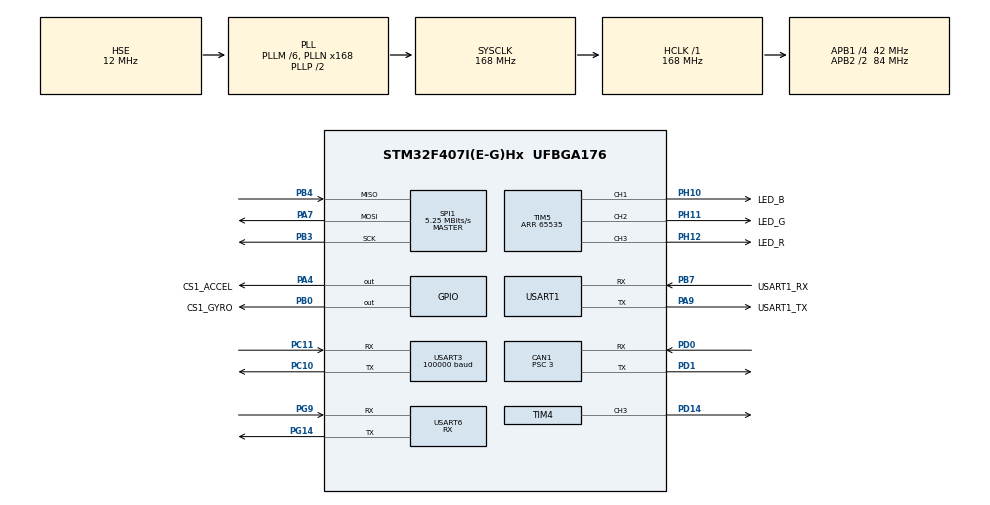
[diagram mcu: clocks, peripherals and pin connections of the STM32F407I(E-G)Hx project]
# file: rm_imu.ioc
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CAN1.ABOM=ENABLE
CAN1.BS1=CAN_BS1_11TQ
CAN1.BS2=CAN_BS2_2TQ
CAN1.CalculateBaudRate=1000000
CAN1.CalculateTimeBit=1000
CAN1.CalculateTimeQuantum=71.42857142857143
CAN1.NART=ENABLE
CAN1.Prescaler=3
Dma.Request0=USART3_RX
Dma.Request1=USART6_RX
Dma.USART3_RX.0.Direction=DMA_PERIPH_TO_MEMORY
Dma.USART3_RX.0.FIFOMode=DMA_FIFOMODE_DISABLE
Dma.USART3_RX.0.Instance=DMA1_Stream1
Dma.USART3_RX.0.MemDataAlignment=DMA_MDATAALIGN_BYTE
Dma.USART3_RX.0.MemInc=DMA_MINC_ENABLE
Dma.USART3_RX.0.Mode=DMA_NORMAL
Dma.USART3_RX.0.PeriphDataAlignment=DMA_PDATAALIGN_BYTE
Dma.USART3_RX.0.PeriphInc=DMA_PINC_DISABLE
Dma.USART3_RX.0.Priority=DMA_PRIORITY_HIGH
Dma.USART6_RX.1.Direction=DMA_PERIPH_TO_MEMORY
Dma.USART6_RX.1.FIFOMode=DMA_FIFOMODE_DISABLE
Dma.USART6_RX.1.Instance=DMA2_Stream1
Dma.USART6_RX.1.MemDataAlignment=DMA_MDATAALIGN_BYTE
Dma.USART6_RX.1.MemInc=DMA_MINC_ENABLE
Dma.USART6_RX.1.Mode=DMA_NORMAL
Dma.USART6_RX.1.PeriphDataAlignment=DMA_PDATAALIGN_BYTE
Dma.USART6_RX.1.PeriphInc=DMA_PINC_DISABLE
Dma.USART6_RX.1.Priority=DMA_PRIORITY_MEDIUM
FREERTOS.Tasks01=defaultTask,0,128,StartDefaultTask,Default,NULL,Dynamic,NULL,NULL;imutask,2,512,imu_task,As external,NULL,Dynamic,NULL,NULL;plotTask,-2,512,plot_task,As external,NULL,Dynamic,NULL,NULL;remoteTask,0,512,remote_task,As external,NULL,Dynamic,NULL,NULL;ledtask,-2,512,led_task,As external,NULL,Dynamic,NULL,NULL;buzzerTask,-3,512,buzzer_task,As external,NULL,Dynamic,NULL,NULL;controlTask,3,512,control_task,As external,NULL,Dynamic,NULL,NULL
Mcu.Family=STM32F4
Mcu.Name=STM32F407I(E-G)Hx
Mcu.Package=UFBGA176
NVIC.CAN1_RX0_IRQn=true\:5\:0\:false\:false\:true\:true\:true\:true\:true
NVIC.DMA1_Stream1_IRQn=true\:5\:0\:false\:false\:true\:true\:false\:true\:true
NVIC.DMA2_Stream1_IRQn=true\:5\:0\:false\:false\:true\:true\:false\:true\:true
NVIC.PriorityGroup=NVIC_PRIORITYGROUP_4
NVIC.TIM6_DAC_IRQn=true\:15\:0\:false\:false\:true\:false\:false\:true\:true
NVIC.TimeBase=TIM6_DAC_IRQn
NVIC.TimeBaseIP=TIM6
NVIC.USART3_IRQn=true\:5\:0\:false\:false\:true\:true\:true\:true\:true
NVIC.USART6_IRQn=true\:5\:0\:false\:false\:true\:true\:true\:true\:true
PA13.Mode=Serial_Wire
PA13.Signal=SYS_JTMS-SWDIO
PA14.Mode=Serial_Wire
PA14.Signal=SYS_JTCK-SWCLK
PA4.GPIO_Label=CS1_ACCEL
PA4.GPIO_Speed=GPIO_SPEED_FREQ_VERY_HIGH
PA4.PinState=GPIO_PIN_SET
PA4.Signal=GPIO_Output
PA7.Mode=Full_Duplex_Master
PA7.Signal=SPI1_MOSI
PA9.GPIO_Label=USART1_TX
PA9.Mode=Asynchronous
PA9.Signal=USART1_TX
PB0.GPIO_Label=CS1_GYRO
PB0.GPIO_Speed=GPIO_SPEED_FREQ_VERY_HIGH
PB0.PinState=GPIO_PIN_SET
PB0.Signal=GPIO_Output
PB3.Mode=Full_Duplex_Master
PB3.Signal=SPI1_SCK
PB4.Mode=Full_Duplex_Master
PB4.Signal=SPI1_MISO
PB7.GPIO_Label=USART1_RX
PB7.Mode=Asynchronous
PB7.Signal=USART1_RX
PC10.Mode=Asynchronous
PC10.Signal=USART3_TX
PC11.Mode=Asynchronous
PC11.Signal=USART3_RX
PD0.Mode=CAN_Activate
PD0.Signal=CAN1_RX
PD1.Mode=CAN_Activate
PD1.Signal=CAN1_TX
PD14.Signal=S_TIM4_CH3
PG14.Mode=Asynchronous
PG14.Signal=USART6_TX
PG9.Mode=Asynchronous
PG9.Signal=USART6_RX
PH0-OSC_IN.Mode=HSE-External-Oscillator
PH0-OSC_IN.Signal=RCC_OSC_IN
PH1-OSC_OUT.Mode=HSE-External-Oscillator
PH1-OSC_OUT.Signal=RCC_OSC_OUT
PH10.GPIO_Label=LED_B
PH10.Signal=S_TIM5_CH1
PH11.GPIO_Label=LED_G
PH11.Signal=S_TIM5_CH2
PH12.GPIO_Label=LED_R
PH12.Signal=S_TIM5_CH3
ProjectManager.HeapSize=0x200
ProjectManager.StackSize=0x400
ProjectManager.TargetToolchain=CMake
RCC.48MHZClocksFreq_Value=84000000
RCC.AHBFreq_Value=168000000
RCC.APB1CLKDivider=RCC_HCLK_DIV4
RCC.APB1Freq_Value=42000000
RCC.APB1TimFreq_Value=84000000
RCC.APB2CLKDivider=RCC_HCLK_DIV2
RCC.APB2Freq_Value=84000000
RCC.APB2TimFreq_Value=168000000
RCC.CortexFreq_Value=168000000
RCC.HCLKFreq_Value=168000000
RCC.HSE_VALUE=12000000
RCC.HSI_VALUE=16000000
RCC.LSE_VALUE=32768
RCC.PLLM=6
RCC.PLLN=168
RCC.PLLSourceVirtual=RCC_PLLSOURCE_HSE
RCC.SYSCLKFreq_VALUE=168000000
RCC.SYSCLKSource=RCC_SYSCLKSOURCE_PLLCLK
RCC.VCOOutputFreq_Value=336000000
SH.S_TIM4_CH3.0=TIM4_CH3,PWM Generation3 CH3
SH.S_TIM5_CH1.0=TIM5_CH1,PWM Generation1 CH1
SH.S_TIM5_CH2.0=TIM5_CH2,PWM Generation2 CH2
SH.S_TIM5_CH3.0=TIM5_CH3,PWM Generation3 CH3
SPI1.BaudRatePrescaler=SPI_BAUDRATEPRESCALER_16
SPI1.CLKPhase=SPI_PHASE_2EDGE
SPI1.CLKPolarity=SPI_POLARITY_HIGH
SPI1.CalculateBaudRate=5.25 MBits/s
SPI1.Direction=SPI_DIRECTION_2LINES
SPI1.Mode=SPI_MODE_MASTER
SPI1.VirtualType=VM_MASTER
TIM4.Channel-PWM\ Generation3\ CH3=TIM_CHANNEL_3
TIM4.Period=249
TIM4.Prescaler=83
TIM4.Pulse-PWM\ Generation3\ CH3=125
TIM5.Channel-PWM\ Generation1\ CH1=TIM_CHANNEL_1
TIM5.Channel-PWM\ Generation2\ CH2=TIM_CHANNEL_2
TIM5.Channel-PWM\ Generation3\ CH3=TIM_CHANNEL_3
TIM5.Period=65535
USART1.VirtualMode=VM_ASYNC
USART3.BaudRate=100000
USART3.Mode=MODE_RX
USART3.Parity=PARITY_EVEN
USART3.VirtualMode=VM_ASYNC
USART3.WordLength=WORDLENGTH_9B
USART6.Mode=MODE_RX
USART6.VirtualMode=VM_ASYNC
VP_FREERTOS_VS_CMSIS_V1.Mode=CMSIS_V1
VP_SYS_VS_tim6.Mode=TIM6
VP_TIM4_VS_ClockSourceINT.Mode=Internal
VP_TIM5_VS_ClockSourceINT.Mode=Internal
board=custom

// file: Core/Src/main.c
/* USER CODE BEGIN Header */
/**
  ******************************************************************************
  * @file           : main.c
  * @brief          : Main program body
  ******************************************************************************
  * @attention
  *
  * Copyright (c) 2026 STMicroelectronics.
  * All rights reserved.
  *
  * This software is licensed under terms that can be found in the LICENSE file
  * in the root directory of this software component.
  * If no LICENSE file comes with this software, it is provided AS-IS.
  *
  ******************************************************************************
  */
/* USER CODE END Header */
#include "main.h"
#include "cmsis_os.h"
#include "can.h"
#include "dma.h"
#include "spi.h"
#include "tim.h"
#include "usart.h"
#include "gpio.h"

void SystemClock_Config(void);
void MX_FREERTOS_Init(void);

int main(void)
{

  /* MCU Configuration--------------------------------------------------------*/

  /* Reset of all peripherals, Initializes the Flash interface and the Systick. */
  HAL_Init();

  /* Configure the system clock */
  SystemClock_Config();

  /* Initialize all configured peripherals */
  MX_GPIO_Init();
  MX_DMA_Init();
  MX_SPI1_Init();
  MX_USART1_UART_Init();
  MX_USART3_UART_Init();
  MX_CAN1_Init();
  MX_TIM5_Init();
  MX_TIM4_Init();
  MX_USART6_UART_Init();

  /* Call init function for freertos objects (in cmsis_os2.c) */
  MX_FREERTOS_Init();

  /* Start scheduler */
  osKernelStart();

  /* We should never get here as control is now taken by the scheduler */

  /* Infinite loop */
  while (1)
  {

  }
}

void SystemClock_Config(void)
{
  RCC_OscInitTypeDef RCC_OscInitStruct = {0};
  RCC_ClkInitTypeDef RCC_ClkInitStruct = {0};

  /** Configure the main internal regulator output voltage
  */
  __HAL_RCC_PWR_CLK_ENABLE();
  __HAL_PWR_VOLTAGESCALING_CONFIG(PWR_REGULATOR_VOLTAGE_SCALE1);

  /** Initializes the RCC Oscillators according to the specified parameters
  * in the RCC_OscInitTypeDef structure.
  */
  RCC_OscInitStruct.OscillatorType = RCC_OSCILLATORTYPE_HSE;
  RCC_OscInitStruct.HSEState = RCC_HSE_ON;
  RCC_OscInitStruct.PLL.PLLState = RCC_PLL_ON;
  RCC_OscInitStruct.PLL.PLLSource = RCC_PLLSOURCE_HSE;
  RCC_OscInitStruct.PLL.PLLM = 6;
  RCC_OscInitStruct.PLL.PLLN = 168;
  RCC_OscInitStruct.PLL.PLLP = RCC_PLLP_DIV2;
  RCC_OscInitStruct.PLL.PLLQ = 4;
  if (HAL_RCC_OscConfig(&RCC_OscInitStruct) != HAL_OK)
  {
    Error_Handler();
  }

  /** Initializes the CPU, AHB and APB buses clocks
  */
  RCC_ClkInitStruct.ClockType = RCC_CLOCKTYPE_HCLK|RCC_CLOCKTYPE_SYSCLK
                              |RCC_CLOCKTYPE_PCLK1|RCC_CLOCKTYPE_PCLK2;
  RCC_ClkInitStruct.SYSCLKSource = RCC_SYSCLKSOURCE_PLLCLK;
  RCC_ClkInitStruct.AHBCLKDivider = RCC_SYSCLK_DIV1;
  RCC_ClkInitStruct.APB1CLKDivider = RCC_HCLK_DIV4;
  RCC_ClkInitStruct.APB2CLKDivider = RCC_HCLK_DIV2;

  if (HAL_RCC_ClockConfig(&RCC_ClkInitStruct, FLASH_LATENCY_5) != HAL_OK)
  {
    Error_Handler();
  }
}

void HAL_TIM_PeriodElapsedCallback(TIM_HandleTypeDef *htim)
{
  if (htim->Instance == TIM6)
  {
    HAL_IncTick();
  }
}

void Error_Handler(void)
{
  __disable_irq();
  while (1)
  {
  }
}

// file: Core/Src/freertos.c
/* USER CODE BEGIN Header */
/**
  ******************************************************************************
  * File Name          : freertos.c
  * Description        : Code for freertos applications
  ******************************************************************************
  * @attention
  *
  * Copyright (c) 2026 STMicroelectronics.
  * All rights reserved.
  *
  * This software is licensed under terms that can be found in the LICENSE file
  * in the root directory of this software component.
  * If no LICENSE file comes with this software, it is provided AS-IS.
  *
  ******************************************************************************
  */
/* USER CODE END Header */

#include "FreeRTOS.h"
#include "task.h"
#include "main.h"
#include "cmsis_os.h"

/* USER CODE BEGIN Includes */
#include "imu_task.h"
#include "remote_task.h"
#include "can_task.h"
/* USER CODE END Includes */

osThreadId defaultTaskHandle;
osThreadId imutaskHandle;
osThreadId usartTaskHandle;
osThreadId remoteTaskHandle;
osThreadId ledtaskHandle;
osThreadId buzzerTaskHandle;
osThreadId controlTaskHandle;

void StartDefaultTask(void const * argument);
extern void imu_task(void const * argument);
extern void usart_task(void const * argument);
extern void remote_task(void const * argument);
extern void led_task(void const * argument);
extern void buzzer_task(void const * argument);
extern void control_task(void const * argument);

void MX_FREERTOS_Init(void); /* (MISRA C 2004 rule 8.1) */

/* GetIdleTaskMemory prototype (linked to static allocation support) */
void vApplicationGetIdleTaskMemory( StaticTask_t **ppxIdleTaskTCBBuffer, StackType_t **ppxIdleTaskStackBuffer, uint32_t *pulIdleTaskStackSize );

/* USER CODE BEGIN GET_IDLE_TASK_MEMORY */
static StaticTask_t xIdleTaskTCBBuffer;
static StackType_t xIdleStack[configMINIMAL_STACK_SIZE];

void vApplicationGetIdleTaskMemory( StaticTask_t **ppxIdleTaskTCBBuffer, StackType_t **ppxIdleTaskStackBuffer, uint32_t *pulIdleTaskStackSize )
{
  *ppxIdleTaskTCBBuffer = &xIdleTaskTCBBuffer;
  *ppxIdleTaskStackBuffer = &xIdleStack[0];
  *pulIdleTaskStackSize = configMINIMAL_STACK_SIZE;
  /* place for user code */
}
/* USER CODE END GET_IDLE_TASK_MEMORY */

void MX_FREERTOS_Init(void) {

  /* Create the thread(s) */
  /* definition and creation of defaultTask */
  osThreadDef(defaultTask, StartDefaultTask, osPriorityNormal, 0, 128);
  defaultTaskHandle = osThreadCreate(osThread(defaultTask), NULL);

  /* definition and creation of imutask */
  osThreadDef(imutask, imu_task, osPriorityHigh, 0, 512);
  imutaskHandle = osThreadCreate(osThread(imutask), NULL);

  /* definition and creation of usartTask */
  osThreadDef(usartTask, usart_task, osPriorityLow, 0, 512);
  usartTaskHandle = osThreadCreate(osThread(usartTask), NULL);

  /* definition and creation of remoteTask */
  osThreadDef(remoteTask, remote_task, osPriorityNormal, 0, 512);
  remoteTaskHandle = osThreadCreate(osThread(remoteTask), NULL);

  /* definition and creation of ledtask */
  osThreadDef(ledtask, led_task, osPriorityLow, 0, 512);
  ledtaskHandle = osThreadCreate(osThread(ledtask), NULL);

  /* definition and creation of buzzerTask */
  osThreadDef(buzzerTask, buzzer_task, osPriorityIdle, 0, 512);
  buzzerTaskHandle = osThreadCreate(osThread(buzzerTask), NULL);

  /* definition and creation of controlTask */
  osThreadDef(controlTask, control_task, osPriorityRealtime, 0, 512);
  controlTaskHandle = osThreadCreate(osThread(controlTask), NULL);

}

void StartDefaultTask(void const * argument)
{
  for(;;)
  {
    osDelay(1);
  }
}
